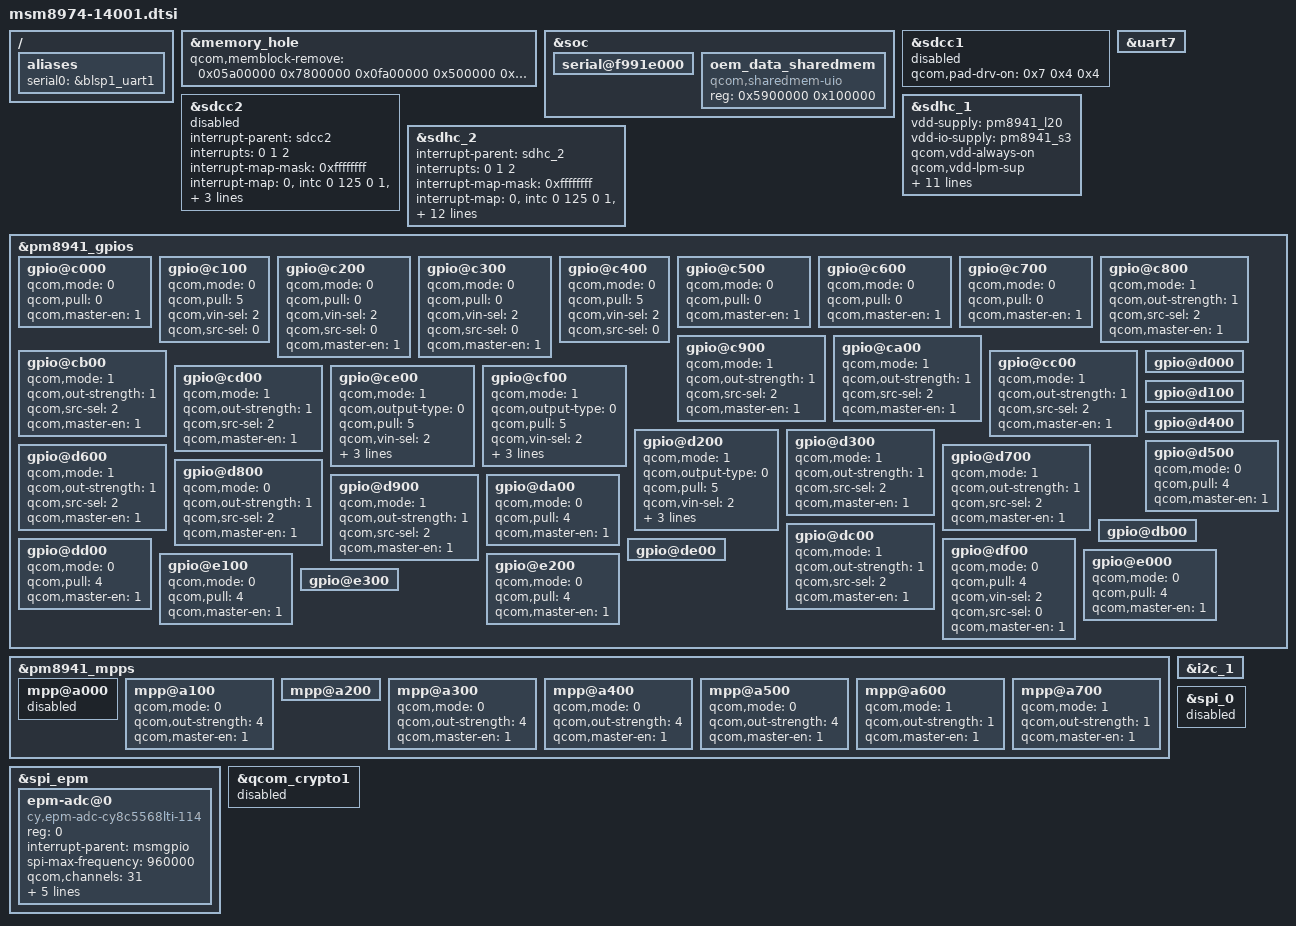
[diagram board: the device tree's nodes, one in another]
/* Copyright (c) 2012-2013, The Linux Foundation. All rights reserved.
 *
 * This program is free software; you can redistribute it and/or modify
 * it under the terms of the GNU General Public License version 2 and
 * only version 2 as published by the Free Software Foundation.
 *
 * This program is distributed in the hope that it will be useful,
 * but WITHOUT ANY WARRANTY; without even the implied warranty of
 * MERCHANTABILITY or FITNESS FOR A PARTICULAR PURPOSE.  See the
 * GNU General Public License for more details.
 */

/include/ "msm8974-14001-panel.dtsi"
/include/ "msm8974-14001-leds.dtsi"
/include/ "msm8974-14001-camera.dtsi"
/include/ "msm8974-14001-input.dtsi"
/include/ "msm8974-14001-usb.dtsi"
/include/ "msm8974-14001-misc.dtsi"
/include/ "msm8974-14001-pm.dtsi"
/include/ "msm8974-14001-nfc.dtsi"
/include/ "msm8974-14001-regulator.dtsi"
/include/ "msm8974-14001-sound.dtsi"

/ {
	aliases {
		serial0 = &blsp1_uart1;
	};
};

&memory_hole {
	qcom,memblock-remove = <0x05a00000 0x7800000  /* MSM8974pro allocation */
				0x0fa00000 0x500000   /* MSM8974pro allocation */
				0x05900000 0x100000>; /* OEM data allocation */
};

&soc {
	serial@f991e000 {
		status = "ok";
	};

	oem_data_sharedmem {
		compatible = "qcom,sharedmem-uio";
		reg = <0x5900000 0x100000>;
		reg-names = "oem_data";
	};
};

&sdcc1 {
	status = "disabled";
};

&sdcc2 {
	#address-cells = <0>;
	interrupt-parent = <&sdcc2>;
	interrupts = <0 1 2>;
	#interrupt-cells = <1>;
	interrupt-map-mask = <0xffffffff>;
	interrupt-map = <0 &intc 0 125 0
			1 &intc 0 220 0
			2 &msmgpio 62 0x3>;
	interrupt-names = "core_irq", "bam_irq", "status_irq";
	cd-gpios = <&msmgpio 62 0x1>;
	status = "disabled";
};

&sdhc_1 {
	vdd-supply = <&pm8941_l20>;
	vdd-io-supply = <&pm8941_s3>;

	qcom,vdd-always-on;
	qcom,vdd-lpm-sup;
	qcom,vdd-voltage-level = <2950000 2950000>;
	qcom,vdd-current-level = <800 500000>;

	qcom,vdd-io-always-on;
	qcom,vdd-io-voltage-level = <1800000 1800000>;
	qcom,vdd-io-current-level = <250 154000>;

	qcom,pad-pull-on = <0x0 0x3 0x3>; /* no-pull, pull-up, pull-up */
	qcom,pad-pull-off = <0x0 0x3 0x3>; /* no-pull, pull-up, pull-up */
	qcom,pad-drv-on = <0x4 0x4 0x4>; /* 10mA, 10mA, 10mA */
	qcom,pad-drv-off = <0x0 0x0 0x0>; /* 2mA, 2mA, 2mA */

	qcom,nonremovable;
	qcom,wakeup-on-idle;
	status = "ok";
};

&sdhc_2 {
	#address-cells = <0>;
	interrupt-parent = <&sdhc_2>;
	interrupts = <0 1 2>;
	#interrupt-cells = <1>;
	interrupt-map-mask = <0xffffffff>;
	interrupt-map = <0 &intc 0 125 0
			1 &intc 0 221 0
			2 &msmgpio 69 0x3>;
	interrupt-names = "hc_irq", "pwr_irq", "status_irq";
	cd-gpios = <&msmgpio 69 0x1>;

	vdd-supply = <&pm8941_l21>;
	vdd-io-supply = <&pm8941_l13>;

	qcom,vdd-voltage-level = <2950000 2950000>;
	qcom,vdd-current-level = <9000 800000>;

	qcom,vdd-io-voltage-level = <1800000 2950000>;
	qcom,vdd-io-current-level = <6 22000>;

	qcom,pad-pull-on = <0x0 0x3 0x3>; /* no-pull, pull-up, pull-up */
	qcom,pad-pull-off = <0x0 0x3 0x3>; /* no-pull, pull-up, pull-up */
	qcom,pad-drv-on = <0x4 0x4 0x4>; /* 10mA, 10mA, 10mA */
	qcom,pad-drv-off = <0x0 0x0 0x0>; /* 2mA, 2mA, 2mA */
	status = "ok";
};

/* Drive strength recommendations for clock line from hardware team is 10 mA.
 * But since the driver has been been using the below values from the start
 * without any problems, continue to use those.
 */
&sdcc1 {
	qcom,pad-drv-on = <0x7 0x4 0x4>; /* 16mA, 10mA, 10mA */
};

&sdcc2 {
	qcom,pad-drv-on = <0x7 0x4 0x4>; /* 16mA, 10mA, 10mA */
};

&sdhc_1 {
	qcom,pad-drv-on = <0x7 0x4 0x4>; /* 16mA, 10mA, 10mA */
};

&sdhc_2 {
	qcom,pad-drv-on = <0x7 0x4 0x4>; /* 16mA, 10mA, 10mA */
};

&uart7 {
	status = "ok";
};

&pm8941_gpios {
	gpio@c000 { /* GPIO 1 */
		qcom,mode = <0>;        /* QPNP_PIN_MODE_DIG_IN */
		qcom,pull = <0>;        /* QPNP_PIN_PULL_UP_30  */
		qcom,master-en = <1>;
	};

	gpio@c100 { /* GPIO 2 */
		qcom,mode = <0>;        /* QPNP_PIN_MODE_DIG_IN */
		qcom,pull = <5>;        /* QPNP_PIN_PULL_UP_30  */
		qcom,vin-sel = <2>;
		qcom,src-sel = <0>;
	};

	gpio@c200 { /* GPIO 3 */
		qcom,mode = <0>;        /* QPNP_PIN_MODE_DIG_IN */
		qcom,pull = <0>;        /* QPNP_PIN_PULL_UP_30  */
		qcom,vin-sel = <2>;
		qcom,src-sel = <0>;	/* QPNP_PIN_SEL_FUNC_CONSTANT */
		qcom,master-en = <1>;
	};

	gpio@c300 { /* GPIO 4 */
		qcom,mode = <0>;        /* QPNP_PIN_MODE_DIG_IN */
		qcom,pull = <0>;        /* QPNP_PIN_PULL_UP_30  */
		qcom,vin-sel = <2>;     /* QPNP_PIN_VIN2  */
		qcom,src-sel = <0>;	/* QPNP_PIN_SEL_FUNC_CONSTANT */
		qcom,master-en = <1>;
	};

	gpio@c400 { /* GPIO 5 */
		qcom,mode = <0>;        /* QPNP_PIN_MODE_DIG_IN */
		qcom,pull = <5>;        /* QPNP_PIN_PULL_UP_30  */
		qcom,vin-sel = <2>;     /* QPNP_PIN_VIN2  */
		qcom,src-sel = <0>;	/* QPNP_PIN_SEL_FUNC_CONSTANT */
	};

	gpio@c500 { /* GPIO 6 */
		qcom,mode = <0>;        /* QPNP_PIN_MODE_DIG_IN */
		qcom,pull = <0>;        /* QPNP_PIN_PULL_UP_30  */
		qcom,master-en = <1>;
	};

	gpio@c600 { /* GPIO 7 */
		qcom,mode = <0>;        /* QPNP_PIN_MODE_DIG_IN */
		qcom,pull = <0>;        /* QPNP_PIN_PULL_UP_30  */
		qcom,master-en = <1>;
	};

	gpio@c700 { /* GPIO 8 */
		qcom,mode = <0>;        /* QPNP_PIN_MODE_DIG_IN */
		qcom,pull = <0>;        /* QPNP_PIN_PULL_UP_30  */
		qcom,master-en = <1>;
	};

	gpio@c800 { /* GPIO 9 */
		qcom,mode = <1>;          /* QPNP_PIN_MODE_DIG_OUT */
		qcom,out-strength = <1>;  /* QPNP_PIN_OUT_STRENGTH_LOW */
		qcom,src-sel = <2>;       /* QPNP_PIN_SEL_FUNC_1  */
		qcom,master-en = <1>;
	};

	gpio@c900 { /* GPIO 10 */
		qcom,mode = <1>;          /* QPNP_PIN_MODE_DIG_OUT */
		qcom,out-strength = <1>;  /* QPNP_PIN_OUT_STRENGTH_LOW */
		qcom,src-sel = <2>;       /* QPNP_PIN_SEL_FUNC_1  */
		qcom,master-en = <1>;
	};

	gpio@ca00 { /* GPIO 11 */
		qcom,mode = <1>;          /* QPNP_PIN_MODE_DIG_OUT */
		qcom,out-strength = <1>;  /* QPNP_PIN_OUT_STRENGTH_LOW */
		qcom,src-sel = <2>;       /* QPNP_PIN_SEL_FUNC_1  */
		qcom,master-en = <1>;
	};

	gpio@cb00 { /* GPIO 12 */
		qcom,mode = <1>;          /* QPNP_PIN_MODE_DIG_OUT */
		qcom,out-strength = <1>;  /* QPNP_PIN_OUT_STRENGTH_LOW */
		qcom,src-sel = <2>;       /* QPNP_PIN_SEL_FUNC_1  */
		qcom,master-en = <1>;
	};

	gpio@cc00 { /* GPIO 13 */
		qcom,mode = <1>;          /* QPNP_PIN_MODE_DIG_OUT */
		qcom,out-strength = <1>;  /* QPNP_PIN_OUT_STRENGTH_LOW */
		qcom,src-sel = <2>;       /* QPNP_PIN_SEL_FUNC_1  */
		qcom,master-en = <1>;
	};

	gpio@cd00 { /* GPIO 14 */
		qcom,mode = <1>;          /* QPNP_PIN_MODE_DIG_OUT */
		qcom,out-strength = <1>;  /* QPNP_PIN_OUT_STRENGTH_LOW */
		qcom,src-sel = <2>;       /* QPNP_PIN_SEL_FUNC_1  */
		qcom,master-en = <1>;
	};

	gpio@ce00 { /* GPIO 15 */
		qcom,mode = <1>;
		qcom,output-type = <0>;
		qcom,pull = <5>;
		qcom,vin-sel = <2>;
		qcom,out-strength = <1>;
		qcom,src-sel = <2>;
		qcom,master-en = <1>;
	};

	gpio@cf00 { /* GPIO 16 */
		qcom,mode = <1>;
		qcom,output-type = <0>;
		qcom,pull = <5>;
		qcom,vin-sel = <2>;
		qcom,out-strength = <1>;
		qcom,src-sel = <2>;       /* QPNP_PIN_SEL_FUNC_2  */
		qcom,master-en = <1>;
	};

	gpio@d000 { /* GPIO 17 */
	};

	gpio@d100 { /* GPIO 18 */
	};

	gpio@d200 { /* GPIO 19 */
		qcom,mode = <1>;		/* QPNP_PIN_MODE_DIG_OUT */
		qcom,output-type = <0>;		/* QPNP_PIN_OUT_BUF_CMOS */
		qcom,pull = <5>;		/* QPNP_PIN_PULL_NO */
		qcom,vin-sel = <2>;		/* QPNP_PIN_VIN2 */
		qcom,out-strength = <1>;	/* QPNP_PIN_OUT_STRENGTH_LOW */
		qcom,src-sel = <0>;		/* QPNP_PIN_SEL_FUNC_CONSTANT */
		qcom,master-en = <1>;
	};

	gpio@d300 { /* GPIO 20 */
		qcom,mode = <1>;          /* QPNP_PIN_MODE_DIG_OUT */
		qcom,out-strength = <1>;  /* QPNP_PIN_OUT_STRENGTH_LOW */
		qcom,src-sel = <2>;       /* QPNP_PIN_SEL_FUNC_1  */
		qcom,master-en = <1>;
	};

	gpio@d400 { /* GPIO 21 */
	};

	gpio@d500 { /* GPIO 22 */
		qcom,mode = <0>;        /* QPNP_PIN_MODE_DIG_IN */
		qcom,pull = <4>;	/* QPNP_PIN_PULL_DN */
		qcom,master-en = <1>;
	};

	gpio@d600 { /* GPIO 23 */
		qcom,mode = <1>;          /* QPNP_PIN_MODE_DIG_OUT */
		qcom,out-strength = <1>;  /* QPNP_PIN_OUT_STRENGTH_LOW */
		qcom,src-sel = <2>;       /* QPNP_PIN_SEL_FUNC_1  */
		qcom,master-en = <1>;
	};

	gpio@d700 { /* GPIO 24 */
		qcom,mode = <1>;          /* QPNP_PIN_MODE_DIG_OUT */
		qcom,out-strength = <1>;  /* QPNP_PIN_OUT_STRENGTH_LOW */
		qcom,src-sel = <2>;       /* QPNP_PIN_SEL_FUNC_1  */
		qcom,master-en = <1>;
	};

	gpio@d800 { /* GPIO 25 */
		qcom,mode = <0>;          /* QPNP_PIN_MODE_DIG_OUT */
		qcom,out-strength = <1>;  /* QPNP_PIN_OUT_STRENGTH_LOW */
		qcom,src-sel = <2>;       /* QPNP_PIN_SEL_FUNC_1  */
		qcom,master-en = <1>;
	};

	gpio@d900 { /* GPIO 26 */
		qcom,mode = <1>;          /* QPNP_PIN_MODE_DIG_OUT */
		qcom,out-strength = <1>;  /* QPNP_PIN_OUT_STRENGTH_LOW */
		qcom,src-sel = <2>;       /* QPNP_PIN_SEL_FUNC_1  */
		qcom,master-en = <1>;
	};

	gpio@da00 { /* GPIO 27 */
		qcom,mode = <0>;        /* QPNP_PIN_MODE_DIG_IN */
		qcom,pull = <4>;	/* QPNP_PIN_PULL_DN */
		qcom,master-en = <1>;
	};

	gpio@db00 { /* GPIO 28 */
	};

	gpio@dc00 { /* GPIO 29 */
		qcom,mode = <1>;          /* QPNP_PIN_MODE_DIG_OUT */
		qcom,out-strength = <1>;  /* QPNP_PIN_OUT_STRENGTH_LOW */
		qcom,src-sel = <2>;       /* QPNP_PIN_SEL_FUNC_1  */
		qcom,master-en = <1>;
	};

	gpio@dd00 { /* GPIO 30 */
		qcom,mode = <0>;        /* QPNP_PIN_MODE_DIG_IN */
		qcom,pull = <4>;	/* QPNP_PIN_PULL_DN */
		qcom,master-en = <1>;
	};

	gpio@de00 { /* GPIO 31 */
	};

	gpio@df00 { /* GPIO 32 */
		qcom,mode = <0>;        /* QPNP_PIN_MODE_DIG_IN */
		qcom,pull = <4>;	/* QPNP_PIN_PULL_DN */
		qcom,vin-sel = <2>;
		qcom,src-sel = <0>;	/* QPNP_PIN_SEL_FUNC_CONSTANT */
		qcom,master-en = <1>;
	};

	gpio@e000 { /* GPIO 33 */
		qcom,mode = <0>;        /* QPNP_PIN_MODE_DIG_IN */
		qcom,pull = <4>;	/* QPNP_PIN_PULL_DN */
		qcom,master-en = <1>;
	};

	gpio@e100 { /* GPIO 34 */
		qcom,mode = <0>;        /* QPNP_PIN_MODE_DIG_IN */
		qcom,pull = <4>;	/* QPNP_PIN_PULL_DN */
		qcom,master-en = <1>;
	};

	gpio@e200 { /* GPIO 35 */
		qcom,mode = <0>;        /* QPNP_PIN_MODE_DIG_IN */
		qcom,pull = <4>;	/* QPNP_PIN_PULL_DN */
		qcom,master-en = <1>;
	};

	gpio@e300 { /* GPIO 36 */
	};
};

&pm8941_mpps {
	mpp@a000 { /* MPP 1 */
		status = "disabled";
	};

	mpp@a100 { /* MPP 2 */
		qcom,mode = <0>;          /* QPNP_PIN_MODE_DIG_IN */
		qcom,out-strength = <4>;  /* QPNP_PIN_PULL_DN */
		qcom,master-en = <1>;
	};

	mpp@a200 { /* MPP 3 */
	};

	mpp@a300 { /* MPP 4 */
		qcom,mode = <0>;          /* QPNP_PIN_MODE_DIG_IN */
		qcom,out-strength = <4>;  /* QPNP_PIN_PULL_DN */
		qcom,master-en = <1>;
	};

	mpp@a400 { /* MPP 5 */
		qcom,mode = <0>;          /* QPNP_PIN_MODE_DIG_IN */
		qcom,out-strength = <4>;  /* QPNP_PIN_PULL_DN */
		qcom,master-en = <1>;
	};

	mpp@a500 { /* MPP 6 */
		qcom,mode = <0>;          /* QPNP_PIN_MODE_DIG_IN */
		qcom,out-strength = <4>;  /* QPNP_PIN_PULL_DN */
		qcom,master-en = <1>;
	};

	mpp@a600 { /* MPP 7 */
		qcom,mode = <1>;          /* QPNP_PIN_MODE_DIG_OUT */
		qcom,out-strength = <1>;  /* QPNP_PIN_OUT_STRENGTH_LOW */
		qcom,master-en = <1>;
	};

	mpp@a700 { /* MPP 8 */
		qcom,mode = <1>;          /* QPNP_PIN_MODE_DIG_OUT */
		qcom,out-strength = <1>;  /* QPNP_PIN_OUT_STRENGTH_LOW */
		qcom,master-en = <1>;
	};
};

&spi_epm {
	epm-adc@0 {
		compatible = "cy,epm-adc-cy8c5568lti-114";
		reg = <0>;
		interrupt-parent = <&msmgpio>;
		spi-max-frequency = <960000>;
		qcom,channels = <31>;
		qcom,gain = <100 100 100 50 100 100 1 100 1 50
				1 100 1 100 50 50 50 50 50 50
				100 50 100 50 50 50 50 50 50 50
				50>;
		qcom,rsense = <2 2 2 200 20 2 1 2 1 30
				1 10 1 30 50 30 500 30 100 30
				100 500 20 200 1000 20 1000 1000 70 200
				50>;
		qcom,channel-type = <0x1540>;
	};
};

&i2c_1 {
	status = "ok";
};

&spi_0 {
	status = "disabled";
};

&qcom_crypto1 {
	status = "disabled";
};
